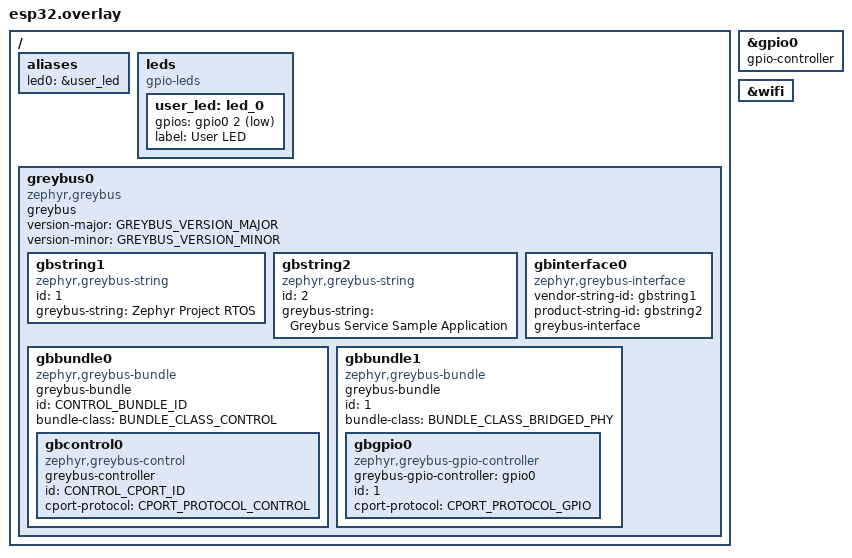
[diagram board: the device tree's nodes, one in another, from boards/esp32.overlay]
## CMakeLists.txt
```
# SPDX-License-Identifier: BSD-3-Clause

cmake_minimum_required(VERSION 3.13.1)
find_package(Zephyr)
project(greybus-net)

zephyr_include_directories(../../../../../include)

include(../../../../cmake/greybus.cmake)

if(CONFIG_GREYBUS_CLICK_MANIFEST_BUILTIN)
  mnfs_to_mnfb(
    ../../../../scripts/manifesto/manifests/${CONFIG_GREYBUS_MIKROBUS_CLICK1_NAME}.mnfs
    ${ZEPHYR_BINARY_DIR}/include/generated/greybus_click_fragment1.mnfb)

  mnfs_to_mnfb(
    ../../../../scripts/manifesto/manifests/${CONFIG_GREYBUS_MIKROBUS_CLICK2_NAME}.mnfs
    ${ZEPHYR_BINARY_DIR}/include/generated/greybus_click_fragment2.mnfb)

  generate_inc_file_for_target(
    app ${ZEPHYR_BINARY_DIR}/include/generated/greybus_click_fragment1.mnfb
    ${ZEPHYR_BINARY_DIR}/include/generated/greybus_click_fragment1_mnfb.inc)

  generate_inc_file_for_target(
    app ${ZEPHYR_BINARY_DIR}/include/generated/greybus_click_fragment2.mnfb
    ${ZEPHYR_BINARY_DIR}/include/generated/greybus_click_fragment2_mnfb.inc)
endif()

target_sources(app PRIVATE src/main.c)
```

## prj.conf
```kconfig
# Greybus options and dependencies
CONFIG_GREYBUS=y
CONFIG_GREYBUS_CONTROL=y
CONFIG_POSIX_API=y
CONFIG_POSIX_THREAD_THREADS_MAX=15
CONFIG_POSIX_SEM_VALUE_MAX=32767
CONFIG_POSIX_MESSAGE_PASSING=y
CONFIG_POSIX_PRIORITY_SCHEDULING=y
CONFIG_THREAD_NAME=y
CONFIG_THREAD_STACK_INFO=y
CONFIG_DYNAMIC_THREAD=y
CONFIG_HEAP_MEM_POOL_SIZE=16384
# CONFIG_GREYBUS_XPORT_TCPIP=y
# for fnmatch()
CONFIG_POSIX_C_LIB_EXT=y

# for putmsg()
CONFIG_XOPEN_STREAMS=y

# for sleep(), getpid()
CONFIG_POSIX_MULTI_PROCESS=y

# for syslog()
CONFIG_XSI_SYSTEM_LOGGING=y

# for sched_get_priority_min(), sched_get_priority_max()
CONFIG_POSIX_PRIORITY_SCHEDULING=y

# Console options
CONFIG_CONSOLE_SUBSYS=y

# Generic networking options
CONFIG_NETWORKING=y
CONFIG_NET_UDP=y
CONFIG_NET_TCP=y
CONFIG_NET_IPV6=y
CONFIG_NET_IPV4=y
CONFIG_NET_SOCKETS=y
CONFIG_NET_SOCKETS_POLL_MAX=16
CONFIG_POSIX_MAX_FDS=16
CONFIG_NET_CONNECTION_MANAGER=y
CONFIG_NET_MAX_CONN=16

# Service advertisement options
CONFIG_DNS_SD=y
CONFIG_NET_HOSTNAME_ENABLE=y
CONFIG_MDNS_RESPONDER=y
CONFIG_MDNS_RESPONDER_DNS_SD=y

# Kernel options
CONFIG_ENTROPY_GENERATOR=y
CONFIG_INIT_STACKS=y

# Logging
CONFIG_NET_LOG=y
CONFIG_LOG=y
CONFIG_NET_STATISTICS=y
CONFIG_PRINTK=y

# Network shell
CONFIG_NET_SHELL=y
CONFIG_SHELL=y

# Network application options and configuration
CONFIG_NET_CONFIG_SETTINGS=y
```

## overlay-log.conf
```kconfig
# CONFIG_LOG=y
# CONFIG_GREYBUS_LOG_LEVEL_DBG=y

# CONFIG_NET_LOG=y

# CONFIG_NET_SOCKETS_LOG_LEVEL_DBG=y
# CONFIG_NET_CONN_LOG_LEVEL_DBG=y
# CONFIG_NET_CONTEXT_LOG_LEVEL_DBG=y
#
# CONFIG_NET_TCP_LOG_LEVEL_DBG=y

# CONFIG_GREYBUS_LOG_LEVEL_DBG=y
# CONFIG_WIFI_LOG_LEVEL_ERR=y
# CONFIG_NET_IPV6_LOG_LEVEL_DBG=y
# CONFIG_NET_SOCKETS_LOG_LEVEL_DBG=y
# CONFIG_PTHREAD_LOG_LEVEL_DBG=y

# CONFIG_NET_IF_LOG_LEVEL_DBG=y
#CONFIG_NET_L2_ETHERNET_LOG_LEVEL_DBG=y

# CONFIG_THREAD_ANALYZER=y 
# CONFIG_THREAD_ANALYZER_USE_PRINTK=y 
# CONFIG_THREAD_ANALYZER_AUTO=y 
# CONFIG_THREAD_ANALYZER_AUTO_INTERVAL=5
```

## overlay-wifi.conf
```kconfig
CONFIG_EARLY_CONSOLE=y

CONFIG_NETWORKING=y
CONFIG_TEST_RANDOM_GENERATOR=y

CONFIG_MAIN_STACK_SIZE=2048
CONFIG_SHELL_STACK_SIZE=2048
CONFIG_NET_TX_STACK_SIZE=2048
CONFIG_NET_RX_STACK_SIZE=2048


CONFIG_NET_PKT_RX_COUNT=10
CONFIG_NET_PKT_TX_COUNT=10
CONFIG_NET_BUF_RX_COUNT=20
CONFIG_NET_BUF_TX_COUNT=20
CONFIG_NET_MAX_CONTEXTS=10
CONFIG_NET_DHCPV4=y

CONFIG_NET_IPV4=n
CONFIG_NET_IPV6=y

CONFIG_NET_TCP=y

CONFIG_INIT_STACKS=y

CONFIG_NET_SHELL=y

CONFIG_NET_STATISTICS=y
CONFIG_NET_STATISTICS_PERIODIC_OUTPUT=n

CONFIG_WIFI=y
CONFIG_WIFI_LOG_LEVEL_ERR=y
CONFIG_NET_L2_WIFI_SHELL=y
# printing of scan results puts pressure on queues in new locking
# design in net_mgmt. So, use a higher timeout for a crowded
# environment.
CONFIG_NET_MGMT_EVENT_QUEUE_TIMEOUT=5000
CONFIG_NET_MGMT_EVENT_QUEUE_SIZE=16
CONFIG_NET_SOCKETS_SERVICE_STACK_SIZE=4096


#CONFIG_NET_LOG=y
#
#CONFIG_NET_SOCKETS_LOG_LEVEL_DBG=y
#CONFIG_NET_CONN_LOG_LEVEL_DBG=y
#CONFIG_NET_CONTEXT_LOG_LEVEL_DBG=y
#
#CONFIG_NET_TCP_LOG_LEVEL_DBG=y

# CONFIG_PTHREAD_LOG_LEVEL_DBG=y

#CONFIG_NET_IF_LOG_LEVEL_DBG=y
#CONFIG_NET_L2_ETHERNET_LOG_LEVEL_DBG=y
```

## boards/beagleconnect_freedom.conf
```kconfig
CONFIG_GPIO=y
CONFIG_GREYBUS_GPIO=y

CONFIG_SPI=y
CONFIG_GREYBUS_SPI=y

CONFIG_I2C=y
CONFIG_GREYBUS_I2C=y

CONFIG_OPT3001=n
CONFIG_LIS2DH=n
CONFIG_LIS2DH_OPER_MODE_LOW_POWER=n
CONFIG_TI_HDC20XX=n
#CONFIG_GREYBUS_CLICK_MANIFEST_CLICKID=y
#CONFIG_GREYBUS_CLICK_MANIFEST_BUILTIN=y
#CONFIG_GREYBUS_MIKROBUS_CLICK1_NAME="RTC-6-CLICK"
#CONFIG_GREYBUS_MIKROBUS_CLICK2_NAME="WEATHER-CLICK"

CONFIG_BT=n

# Disable TCP and IPv4 (TCP disabled to avoid heavy traffic)
CONFIG_NET_TCP=y
CONFIG_NET_IPV4=n

CONFIG_NET_CONFIG_NEED_IPV6=y
CONFIG_NET_CONFIG_NEED_IPV4=n
CONFIG_NET_CONFIG_MY_IPV4_ADDR=""
CONFIG_NET_CONFIG_PEER_IPV4_ADDR=""

CONFIG_NET_L2_IEEE802154=y
CONFIG_NET_L2_IEEE802154_SHELL=y
CONFIG_NET_L2_IEEE802154_LOG_LEVEL_INF=y

CONFIG_IEEE802154_CC13XX_CC26XX=n
CONFIG_NET_CONFIG_IEEE802154_CHANNEL=1
CONFIG_IEEE802154_CC13XX_CC26XX_SUB_GHZ=y
CONFIG_IEEE802154_CC13XX_CC26XX_SUB_GHZ_NUM_RX_BUF=6

# MCUBOOT
CONFIG_BOOTLOADER_MCUBOOT=y
CONFIG_MCUBOOT_SIGNATURE_KEY_FILE="bootloader/mcuboot/root-rsa-2048.pem"
CONFIG_MCUBOOT_IMG_MANAGER=y
CONFIG_MCUBOOT_SHELL=y
```

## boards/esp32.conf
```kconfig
CONFIG_GPIO=y
CONFIG_GPIO_ESP32=y
CONFIG_GREYBUS_GPIO=y

CONFIG_ESP32_WIFI_STA_AUTO_DHCPV4=y
```

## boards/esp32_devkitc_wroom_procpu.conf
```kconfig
CONFIG_WIFI=y

CONFIG_NETWORKING=y
CONFIG_NET_L2_ETHERNET=y

CONFIG_NET_IPV6=n
CONFIG_NET_IPV4=y
CONFIG_NET_DHCPV4=y
CONFIG_ESP32_WIFI_STA_AUTO_DHCPV4=y

CONFIG_GPIO=y
CONFIG_GPIO_ESP32=y
CONFIG_GREYBUS_GPIO=y
```

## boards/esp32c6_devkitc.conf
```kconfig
CONFIG_WIFI=y
CONFIG_WIFI_ESP32=y

CONFIG_NETWORKING=y
CONFIG_NET_L2_ETHERNET=y

CONFIG_NET_IPV6=n
CONFIG_NET_IPV4=y
CONFIG_NET_DHCPV4=y
CONFIG_ESP32_WIFI_STA_AUTO_DHCPV4=y

CONFIG_GPIO=y
CONFIG_GPIO_ESP32=y
CONFIG_GREYBUS_GPIO=y
```

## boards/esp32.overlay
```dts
/*
 * Copyright (c) 2024 
 *
 * SPDX-License-Identifier: BSD-3-Clause
 */

#include <dt-bindings/greybus/greybus.h>
#include <dt-bindings/gpio/gpio.h>
// #include <dt-bindings/i2c/i2c.h>

/ {
    aliases {
        led0 = &user_led;
    };

    leds {
        compatible = "gpio-leds";
        user_led: led_0 {
            gpios = <&gpio0 2 GPIO_ACTIVE_LOW>;
            label = "User LED";
        };
    };

    // resources {
    //     compatible = "test,greybus-i2c";
    //     test-i2c = <&i2c0>;
    // };

    greybus0: greybus0 {
        compatible = "zephyr,greybus";
        greybus;
        status = "okay";
    };
};

// &i2c0 {
//     status = "okay";
//     clock-frequency = <I2C_BITRATE_STANDARD>;
//     pinctrl-0 = <&i2c0_default>;
//     pinctrl-names = "default";
// };

&gpio0 {
    status = "okay";
    gpio-controller;
    #gpio-cells = <2>;
};

&wifi {
    status = "okay";
};

&greybus0 {
    status = "okay";
    version-major = <GREYBUS_VERSION_MAJOR>;
    version-minor = <GREYBUS_VERSION_MINOR>;

    gbstring1: gbstring1 {
        status = "okay";
        compatible = "zephyr,greybus-string";
        id = <1>;
        greybus-string = "Zephyr Project RTOS";
    };

    gbstring2: gbstring2 {
        status = "okay";
        compatible = "zephyr,greybus-string";
        id = <2>;
        greybus-string = "Greybus Service Sample Application";
    };

    gbinterface0 {
        status = "okay";
        compatible = "zephyr,greybus-interface";
        vendor-string-id = <&gbstring1>;
        product-string-id = <&gbstring2>;
        greybus-interface;
    };

    gbbundle0 {
        status = "okay";
        compatible = "zephyr,greybus-bundle";
        greybus-bundle;
        id = <CONTROL_BUNDLE_ID>;
        bundle-class = <BUNDLE_CLASS_CONTROL>;

        gbcontrol0 {
            status = "okay";
            compatible = "zephyr,greybus-control";
            greybus-controller;
            id = <CONTROL_CPORT_ID>;
            cport-protocol = <CPORT_PROTOCOL_CONTROL>;
        };
    };

    gbbundle1 {
        status = "okay";
        compatible = "zephyr,greybus-bundle";
        greybus-bundle;
        id = <1>;
        bundle-class = <BUNDLE_CLASS_BRIDGED_PHY>;

        gbgpio0 {
            status = "okay";
            compatible = "zephyr,greybus-gpio-controller";
            greybus-gpio-controller = <&gpio0>;
            id = <1>;
            cport-protocol = <CPORT_PROTOCOL_GPIO>;
        };
    };
};
```

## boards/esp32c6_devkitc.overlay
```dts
/*
 * Copyright (c) 2024 
 *
 * SPDX-License-Identifier: BSD-3-Clause
 */

#include <dt-bindings/greybus/greybus.h>
#include <dt-bindings/gpio/gpio.h>
// #include <dt-bindings/i2c/i2c.h>

/ {
    aliases {
        led0 = &user_led;
    };

    leds {
        compatible = "gpio-leds";
        user_led: led_0 {
            gpios = <&gpio0 8 GPIO_ACTIVE_LOW>;
            label = "User LED";
        };
    };

    // resources {
    //     compatible = "test,greybus-i2c";
    //     test-i2c = <&i2c0>;
    // };

    greybus0: greybus0 {
        compatible = "zephyr,greybus";
        greybus;
        status = "okay";
    };
};

&wifi {
    status = "okay";
};

&gpio0 {
    status = "okay";
    gpio-controller;
    #gpio-cells = <2>;
};


&greybus0 {
    status = "okay";
    version-major = <GREYBUS_VERSION_MAJOR>;
    version-minor = <GREYBUS_VERSION_MINOR>;

    gbstring1: gbstring1 {
        status = "okay";
        compatible = "zephyr,greybus-string";
        id = <1>;
        greybus-string = "Zephyr Project RTOS";
    };

    gbstring2: gbstring2 {
        status = "okay";
        compatible = "zephyr,greybus-string";
        id = <2>;
        greybus-string = "Greybus Service Sample Application";
    };

    gbinterface0 {
        status = "okay";
        compatible = "zephyr,greybus-interface";
        vendor-string-id = <&gbstring1>;
        product-string-id = <&gbstring2>;
        greybus-interface;
    };

    gbbundle0 {
        status = "okay";
        compatible = "zephyr,greybus-bundle";
        greybus-bundle;
        id = <CONTROL_BUNDLE_ID>;
        bundle-class = <BUNDLE_CLASS_CONTROL>;

        gbcontrol0 {
            status = "okay";
            compatible = "zephyr,greybus-control";
            greybus-controller;
            id = <CONTROL_CPORT_ID>;
            cport-protocol = <CPORT_PROTOCOL_CONTROL>;
        };
    };

    gbbundle1 {
        status = "okay";
        compatible = "zephyr,greybus-bundle";
        greybus-bundle;
        id = <1>;
        bundle-class = <BUNDLE_CLASS_BRIDGED_PHY>;

        gbgpio0 {
            status = "okay";
            compatible = "zephyr,greybus-gpio-controller";
            greybus-gpio-controller = <&gpio0>;
            id = <1>;
            cport-protocol = <CPORT_PROTOCOL_GPIO>;
        };
    };

};
```

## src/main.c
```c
/*
 * Copyright (c) 2109 Friedt Professional Engineering Services, Inc
 *
 * SPDX-License-Identifier: BSD-3-Clause
 */

#include <stdio.h>
#include <zephyr/kernel.h>

int main(void)
{
}
```
